# STM32MP157 register map
File version: 1.6
CPU: CM4 r0p1, little endian, no MPU, FPU, 4 interrupt priority bits
Registers are 32-bit, read-write, reset 0x0 unless marked. A register's access mark holds for its fields unless they carry their own. Offsets are from the block's base; [hi:lo] are bit positions.

## LTDC
Base 0x5A001000
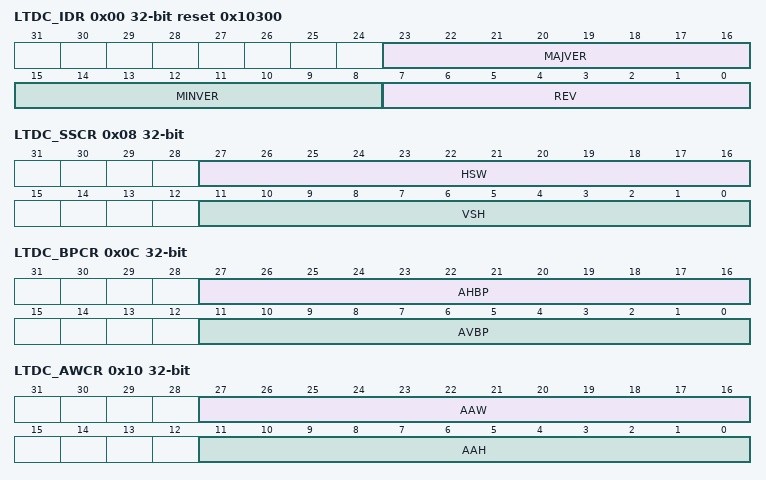
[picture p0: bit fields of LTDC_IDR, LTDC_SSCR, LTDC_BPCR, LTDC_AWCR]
0x00 LTDC_IDR ro reset 0x10300 — LTDC identification register
  [23:16] MAJVER, [15:8] MINVER, [7:0] REV
0x04 LTDC_LCR ro reset 0x2 — LDTC layer count register
  [7:0] LNBR
0x08 LTDC_SSCR — This register defines the number of horizontal synchronization pixels minus 1 and the number of vertical synchronization lines minus 1. Refer to Figure274 and Section36.4: LTDC programmable parameters for an example of configuration.
  [27:16] HSW, [11:0] VSH
0x0C LTDC_BPCR — This register defines the accumulated number of horizontal synchronization and back porch pixels minus 1 (HSYNCwidth+HBP-1) and the accumulated number of vertical synchronization and back porch lines minus 1 (VSYNCheight+VBP-1). Refer to Figure274 and Section36.4: LTDC programmable parameters for an example of configuration.
  [27:16] AHBP, [11:0] AVBP
0x10 LTDC_AWCR — This register defines the accumulated number of horizontal synchronization, back porch and active pixels minus 1 (HSYNC width+HBP+activewidth-1) and the accumulated number of vertical synchronization, back porch lines and active lines minus 1 (VSYNCheight+BVBP+activeheight-1). Refer to Figure274 and Section36.4: LTDC programmable parameters for an example of configuration.
  [27:16] AAW, [11:0] AAH
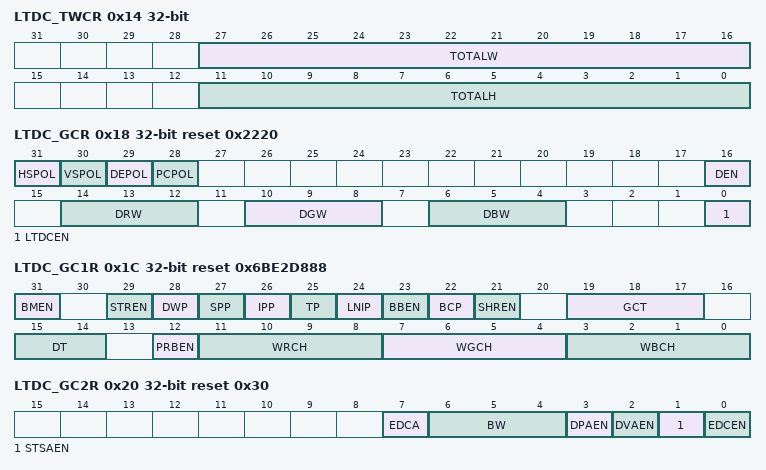
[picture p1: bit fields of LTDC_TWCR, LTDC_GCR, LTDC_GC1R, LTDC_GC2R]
0x14 LTDC_TWCR — This register defines the accumulated number of horizontal synchronization, back porch, active and front porch pixels minus 1 (HSYNCwidth+HBP+activewidth+HFP-1) and the accumulated number of vertical synchronization, back porch lines, active and front lines minus 1 (VSYNCheight+BVBP+activeheight+VFP-1). Refer to Figure274 and Section36.4: LTDC programmable parameters for an example of configuration.
  [27:16] TOTALW, [11:0] TOTALH
0x18 LTDC_GCR access per field reset 0x2220 — This register defines the global configuration of the LCD-TFT controller.
  [31] HSPOL rw, [30] VSPOL rw, [29] DEPOL rw, [28] PCPOL rw, [16] DEN rw, [14:12] DRW ro, [10:8] DGW ro, [6:4] DBW ro, [0] LTDCEN rw
0x1C LTDC_GC1R ro reset 0x6BE2D888 — LTDC global configuration 1 register
  [31] BMEN, [29] STREN, [28] DWP, [27] SPP, [26] IPP, [25] TP, [24] LNIP, [23] BBEN, [22] BCP, [21] SHREN, [19:17] GCT, [15:14] DT, [12] PRBEN, [11:8] WRCH, [7:4] WGCH, [3:0] WBCH
0x20 LTDC_GC2R ro reset 0x30 — LTDC global configuration 2 register
  [7] EDCA, [6:4] BW, [3] DPAEN, [2] DVAEN, [1] STSAEN, [0] EDCEN
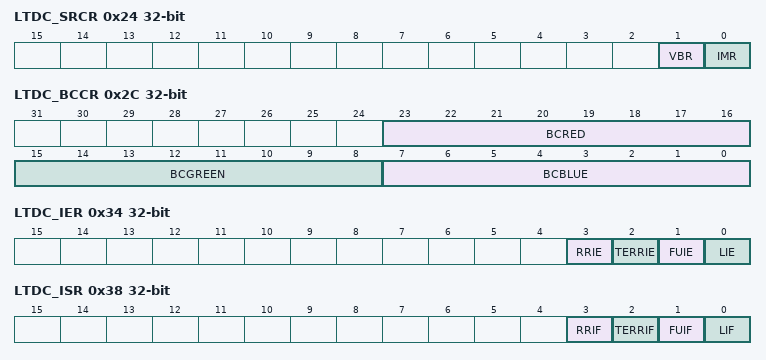
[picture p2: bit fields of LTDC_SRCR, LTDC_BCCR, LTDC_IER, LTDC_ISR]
0x24 LTDC_SRCR — This register allows to reload either immediately or during the vertical blanking period, the shadow registers values to the active registers. The shadow registers are all Layer1 and Layer2 registers except the LTDC_L1CLUTWR and the LTDC_L2CLUTWR.
  [1] VBR, [0] IMR
0x2C LTDC_BCCR — This register defines the background color (RGB888).
  [23:16] BCRED, [15:8] BCGREEN, [7:0] BCBLUE
0x34 LTDC_IER — This register determines which status flags generate an interrupt request by setting the corresponding bit to 1.
  [3] RRIE, [2] TERRIE, [1] FUIE, [0] LIE
0x38 LTDC_ISR ro — This register returns the interrupt status flag.
  [3] RRIF, [2] TERRIF, [1] FUIF, [0] LIF
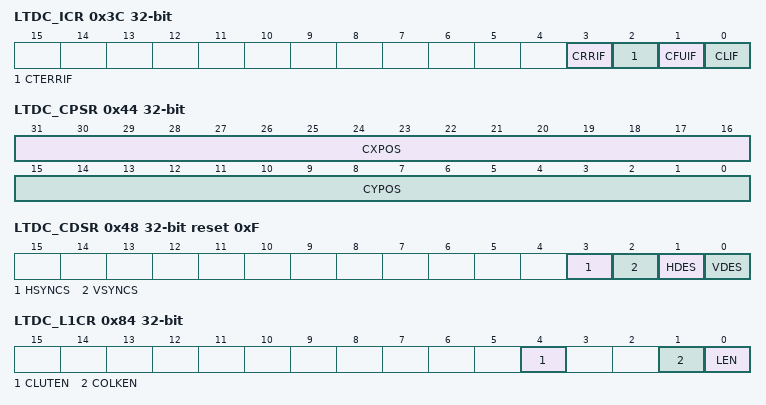
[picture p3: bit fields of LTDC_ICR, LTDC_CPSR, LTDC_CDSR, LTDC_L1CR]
0x3C LTDC_ICR wo — LTDC Interrupt Clear Register
  [3] CRRIF, [2] CTERRIF, [1] CFUIF, [0] CLIF
0x40 LTDC_LIPCR — This register defines the position of the line interrupt. The line value to be programmed depends on the timings parameters. Refer to Figure274.
  [11:0] LIPOS
0x44 LTDC_CPSR ro — LTDC current position status register
  [31:16] CXPOS, [15:0] CYPOS
0x48 LTDC_CDSR ro reset 0xF — This register returns the status of the current display phase which is controlled by the HSYNC, VSYNC, and horizontal/vertical DE signals. Example: if the current display phase is the vertical synchronization, the VSYNCS bit is set (active high). If the current display phase is the horizontal synchronization, the HSYNCS bit is active high.
  [3] HSYNCS, [2] VSYNCS, [1] HDES, [0] VDES
0x84 LTDC_L1CR — LTDC layer 1 control register
  [4] CLUTEN, [1] COLKEN, [0] LEN
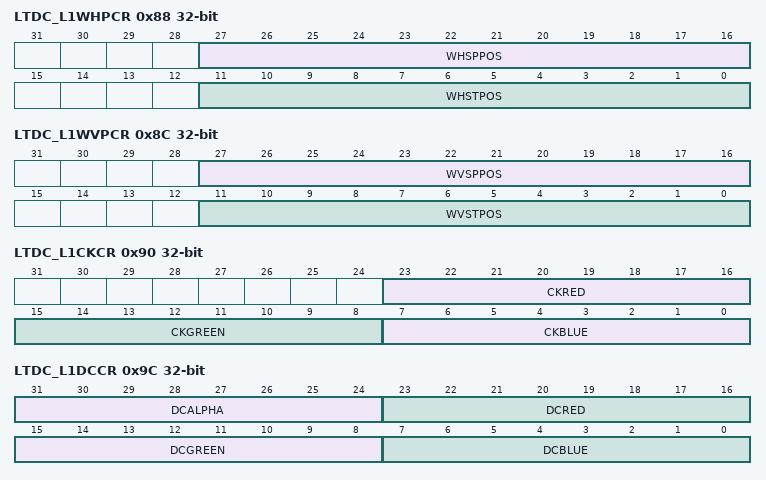
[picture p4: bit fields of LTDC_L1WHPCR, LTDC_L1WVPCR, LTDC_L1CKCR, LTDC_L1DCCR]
0x88 LTDC_L1WHPCR — This register defines the horizontal position (first and last pixel) of the layer 1 or 2 window. The first visible pixel of a line is the programmed value of AHBP[11:0] bits + 1 in the LTDC_BPCR register. The last visible pixel of a line is the programmed value of AAW[11:0] bits in the LTDC_AWCR register.
  [27:16] WHSPPOS, [11:0] WHSTPOS
0x8C LTDC_L1WVPCR — This register defines the vertical position (first and last line) of the layer1 or 2 window. The first visible line of a frame is the programmed value of AVBP[11:0] bits + 1 in the register LTDC_BPCR register. The last visible line of a frame is the programmed value of AAH[11:0] bits in the LTDC_AWCR register.
  [27:16] WVSPPOS, [11:0] WVSTPOS
0x90 LTDC_L1CKCR — This register defines the color key value (RGB), that is used by the color keying.
  [23:16] CKRED, [15:8] CKGREEN, [7:0] CKBLUE
0x94 LTDC_L1PFCR — This register defines the pixel format that is used for the stored data in the frame buffer of a layer. The pixel data is read from the frame buffer and then transformed to the internal format 8888 (ARGB).
  [2:0] PF
0x98 LTDC_L1CACR reset 0xFF — This register defines the constant alpha value (divided by 255 by hardware), that is used in the alpha blending. Refer to LTDC_LxBFCR register.
  [7:0] CONSTA
0x9C LTDC_L1DCCR — This register defines the default color of a layer in the format ARGB. The default color is used outside the defined layer window or when a layer is disabled. The reset value of 0x00000000 defines a transparent black color.
  [31:24] DCALPHA, [23:16] DCRED, [15:8] DCGREEN, [7:0] DCBLUE
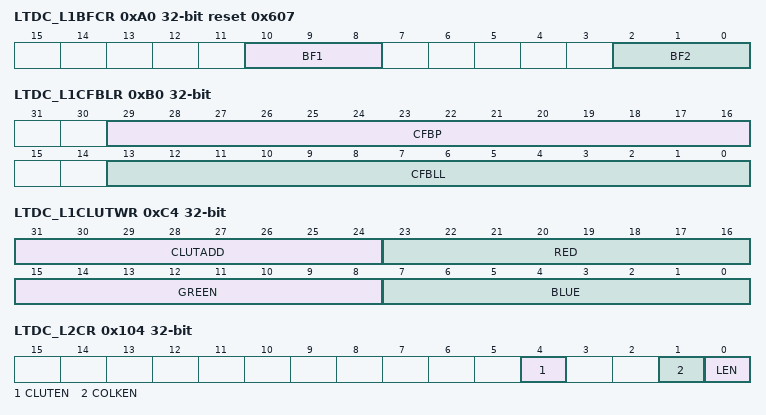
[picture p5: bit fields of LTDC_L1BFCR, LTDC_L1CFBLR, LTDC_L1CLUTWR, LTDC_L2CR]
0xA0 LTDC_L1BFCR reset 0x607 — This register defines the blending factors F1 and F2. The general blending formula is: BC = BF1 x C + BF2 x Cs BC = blended color BF1 = blend factor 1 C = current layer color BF2 = blend factor 2 Cs = subjacent layers blended color
  [10:8] BF1, [2:0] BF2
0xAC LTDC_L1CFBAR — This register defines the color frame buffer start address which has to point to the address where the pixel data of the top left pixel of a layer is stored in the frame buffer.
  [31:0] CFBADD
0xB0 LTDC_L1CFBLR — This register defines the color frame buffer line length and pitch.
  [29:16] CFBP, [13:0] CFBLL
0xB4 LTDC_L1CFBLNR — This register defines the number of lines in the color frame buffer.
  [11:0] CFBLNBR
0xC4 LTDC_L1CLUTWR wo — This register defines the CLUT address and the RGB value.
  [31:24] CLUTADD, [23:16] RED, [15:8] GREEN, [7:0] BLUE
0x104 LTDC_L2CR — LTDC layer 2 control register
  [4] CLUTEN, [1] COLKEN, [0] LEN
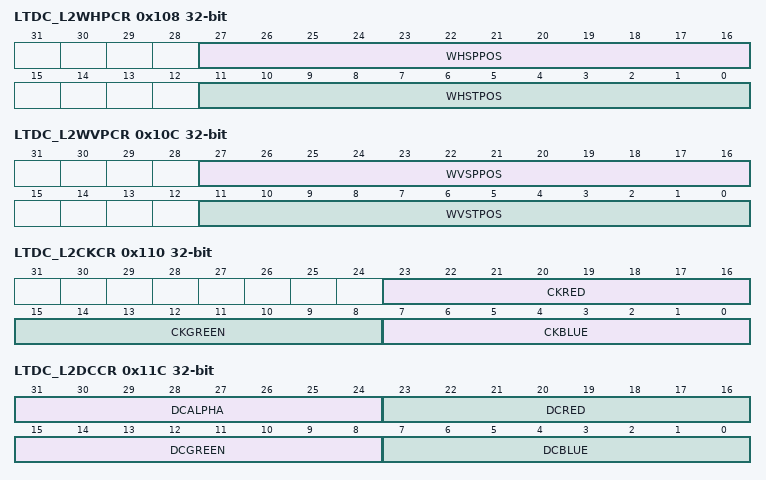
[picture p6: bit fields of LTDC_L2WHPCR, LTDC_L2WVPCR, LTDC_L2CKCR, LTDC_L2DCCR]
0x108 LTDC_L2WHPCR — This register defines the horizontal position (first and last pixel) of the layer 1 or 2 window. The first visible pixel of a line is the programmed value of AHBP[11:0] bits + 1 in the LTDC_BPCR register. The last visible pixel of a line is the programmed value of AAW[11:0] bits in the LTDC_AWCR register.
  [27:16] WHSPPOS, [11:0] WHSTPOS
0x10C LTDC_L2WVPCR — This register defines the vertical position (first and last line) of the layer1 or 2 window. The first visible line of a frame is the programmed value of AVBP[11:0] bits + 1 in the register LTDC_BPCR register. The last visible line of a frame is the programmed value of AAH[11:0] bits in the LTDC_AWCR register.
  [27:16] WVSPPOS, [11:0] WVSTPOS
0x110 LTDC_L2CKCR — This register defines the color key value (RGB), that is used by the color keying.
  [23:16] CKRED, [15:8] CKGREEN, [7:0] CKBLUE
0x114 LTDC_L2PFCR — This register defines the pixel format that is used for the stored data in the frame buffer of a layer. The pixel data is read from the frame buffer and then transformed to the internal format 8888 (ARGB).
  [2:0] PF
0x118 LTDC_L2CACR reset 0xFF — This register defines the constant alpha value (divided by 255 by hardware), that is used in the alpha blending. Refer to LTDC_LxBFCR register.
  [7:0] CONSTA
0x11C LTDC_L2DCCR — This register defines the default color of a layer in the format ARGB. The default color is used outside the defined layer window or when a layer is disabled. The reset value of 0x00000000 defines a transparent black color.
  [31:24] DCALPHA, [23:16] DCRED, [15:8] DCGREEN, [7:0] DCBLUE
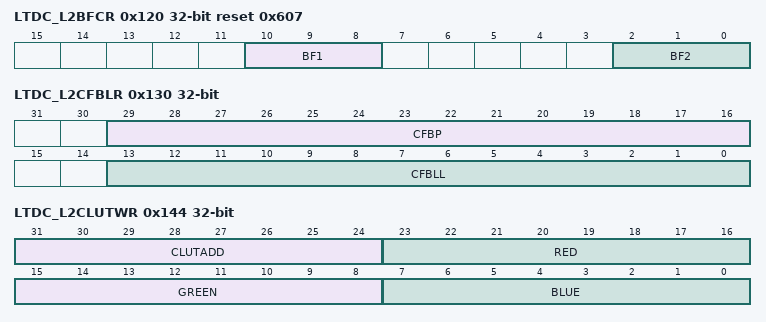
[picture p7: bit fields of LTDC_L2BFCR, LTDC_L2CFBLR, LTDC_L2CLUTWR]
0x120 LTDC_L2BFCR reset 0x607 — This register defines the blending factors F1 and F2. The general blending formula is: BC = BF1 x C + BF2 x Cs BC = blended color BF1 = blend factor 1 C = current layer color BF2 = blend factor 2 Cs = subjacent layers blended color
  [10:8] BF1, [2:0] BF2
0x12C LTDC_L2CFBAR — This register defines the color frame buffer start address which has to point to the address where the pixel data of the top left pixel of a layer is stored in the frame buffer.
  [31:0] CFBADD
0x130 LTDC_L2CFBLR — This register defines the color frame buffer line length and pitch.
  [29:16] CFBP, [13:0] CFBLL
0x134 LTDC_L2CFBLNR — This register defines the number of lines in the color frame buffer.
  [11:0] CFBLNBR
0x144 LTDC_L2CLUTWR wo — This register defines the CLUT address and the RGB value.
  [31:24] CLUTADD, [23:16] RED, [15:8] GREEN, [7:0] BLUE
